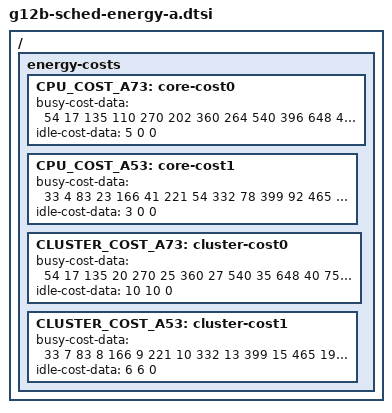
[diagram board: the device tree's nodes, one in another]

/ {
	energy-costs {
		CPU_COST_A73: core-cost0 {
			busy-cost-data = <
				54    17
				135   110
				270   202
				360   264
				540   396
				648   470
				755   557
				816   620
				868   699
				920   759
				/*1024  1024*/
			>;
			idle-cost-data = <
				5
				0
				0
			>;
		};
		CPU_COST_A53: core-cost1 {
			busy-cost-data = <
				33  4
				83  23
				166 41
				221 54
				332 78
				399 92
				465 116
				503 135
				535 162
				567 184
				599 224
				631 279
			>;
			idle-cost-data = <
				3
				0
				0
			>;
		};
		CLUSTER_COST_A73: cluster-cost0 {
			busy-cost-data = <
				54   17
				135  20
				270  25
				360  27
				540  35
				648  40
				755  49
				816  57
				868  54
				920  64
				/*1024 79*/
			>;
			idle-cost-data = <
				10
				10
				0
			>;
		};
		CLUSTER_COST_A53: cluster-cost1 {
			busy-cost-data = <
				33  7
				83  8
				166 9
				221 10
				332 13
				399 15
				465 19
				503 23
				535 26
				567 31
				599 36
				631 42
			>;
			idle-cost-data = <
				6
				6
				0
			>;
		};
	};
};
